AUTOSAR XML (schema 4-2-1)
package /RootP_ASWC_M412
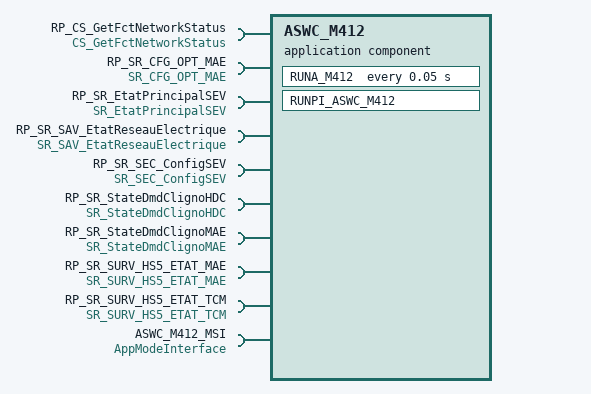
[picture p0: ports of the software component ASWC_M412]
  application sw component type ASWC_M412
    provide/require port PRP_SR_ManTurnIDReq: nonqueued-receiver-com-spec{data-element=ManTurnIDReq, enable-update=0, handle-data-status=1, handle-never-received=0, init-value=CONST_t_IndicatorDirection_0:0}, provided-required-interface=SR_ManTurnIDReq
    10 x require port:
      RP_CS_GetFctNetworkStatus: required-interface=CS_GetFctNetworkStatus
      RP_SR_CFG_OPT_MAE: nonqueued-receiver-com-spec{data-element=CFG_OPT_MAE, enable-update=0, handle-data-status=1, handle-never-received=0, init-value=CONST_tBYTE_0:0}, required-interface=SR_CFG_OPT_MAE
      RP_SR_EtatPrincipalSEV: nonqueued-receiver-com-spec{data-element=EtatPrincipalSEV, enable-update=0, handle-data-status=1, handle-never-received=0, init-value=CONST_EtatPrincipalSEV_t_SEV_SEV_Arret:105}, required-interface=SR_EtatPrincipalSEV
      RP_SR_SAV_EtatReseauElectrique: nonqueued-receiver-com-spec{data-element=SAV_EtatReseauElectrique, enable-update=0, handle-data-status=1, handle-never-received=0, init-value=CONST_t_cGEE_1_0:0}, required-interface=SR_SAV_EtatReseauElectrique
      RP_SR_SEC_ConfigSEV: nonqueued-receiver-com-spec{data-element=SEC_ConfigSEV, enable-update=0, handle-data-status=1, handle-never-received=0, init-value=CONST_t_cCSEV_4:4}, required-interface=SR_SEC_ConfigSEV
      RP_SR_StateDmdClignoHDC: nonqueued-receiver-com-spec{data-element=StateDmdClignoHDC, enable-update=0, handle-data-status=1, handle-never-received=0, init-value=CONST_StateDmdClignoHDC_t_IndicatorDirection_cNoID:0}, required-interface=SR_StateDmdClignoHDC
      RP_SR_StateDmdClignoMAE: nonqueued-receiver-com-spec{data-element=StateDmdClignoMAE, enable-update=0, handle-data-status=1, handle-never-received=0, init-value=CONST_StateDmdClignoMAE_t_IndicatorDirection_cNoID:0}, required-interface=SR_StateDmdClignoMAE
      RP_SR_SURV_HS5_ETAT_MAE: nonqueued-receiver-com-spec{data-element=deSurvHs5EtatMae, alive-timeout=600, enable-update=0, handle-data-status=1, handle-never-received=0, init-value=CONST_tLOG_0:0}, required-interface=SR_SURV_HS5_ETAT_MAE
      RP_SR_SURV_HS5_ETAT_TCM: nonqueued-receiver-com-spec{data-element=deSurvHs5EtatTcm, alive-timeout=300, enable-update=0, handle-data-status=1, handle-never-received=0, init-value=CONST_tLOG_0:0}, required-interface=SR_SURV_HS5_ETAT_TCM
      ASWC_M412_MSI: required-interface=AppModeInterface
    behavior IB_ASWC_M412: data-type-mapping=ApplicationModeMapping, handle-termination-and-restart=NO-SUPPORT
      timing event RUNA_M412_Cyclic: start-on-event=RUNA_M412, period=0.05
        disabled-mode:
          ASWC_M412_MSI.AppMode.APP_WAKEUP
          ASWC_M412_MSI.AppMode.APP_OFF
          ASWC_M412_MSI.AppMode.APP_SYNC_INIT
          ASWC_M412_MSI.AppMode.APP_CONFIG
      swc mode switch event RUNPI_ASWC_M412_ENTRY: start-on-event=RUNPI_ASWC_M412, activation=ON-ENTRY, mode=ASWC_M412_MSI.AppMode.APP_WAKEUP
      runnable RUNA_M412
        data-read-access:
          9 x access:
            dra_RP_SR_EtatPrincipalSEV_EtatPrincipalSEV: accessed-variable=RP_SR_EtatPrincipalSEV.EtatPrincipalSEV
            dra_RP_SR_SAV_EtatReseauElectrique_SAV_EtatReseauElectrique: accessed-variable=RP_SR_SAV_EtatReseauElectrique.SAV_EtatReseauElectrique
            dra_RP_SR_SEC_ConfigSEV_SEC_ConfigSEV: accessed-variable=RP_SR_SEC_ConfigSEV.SEC_ConfigSEV
            dra_RP_SR_StateDmdClignoHDC_StateDmdClignoHDC: accessed-variable=RP_SR_StateDmdClignoHDC.StateDmdClignoHDC
            dra_RP_SR_StateDmdClignoMAE_StateDmdClignoMAE: accessed-variable=RP_SR_StateDmdClignoMAE.StateDmdClignoMAE
            dra_RP_SR_SURV_HS5_ETAT_MAE_deSurvHs5EtatMae: accessed-variable=RP_SR_SURV_HS5_ETAT_MAE.deSurvHs5EtatMae
            dra_RP_SR_SURV_HS5_ETAT_TCM_deSurvHs5EtatTcm: accessed-variable=RP_SR_SURV_HS5_ETAT_TCM.deSurvHs5EtatTcm
            dra_RP_SR_CFG_OPT_MAE_CFG_OPT_MAE: accessed-variable=RP_SR_CFG_OPT_MAE.CFG_OPT_MAE
            dra_PRP_SR_ManTurnIDReq_ManTurnIDReq: accessed-variable=PRP_SR_ManTurnIDReq.ManTurnIDReq
        data-write-access:
          access dwa_PRP_SR_ManTurnIDReq_ManTurnIDReq: accessed-variable=PRP_SR_ManTurnIDReq.ManTurnIDReq
        sync call sscp_RUNA_M412_CS_GetFctNetworkStatus_Get: operation=RP_CS_GetFctNetworkStatus.Get, timeout=0
      runnable RUNPI_ASWC_M412
package /RootP_Implementatation
  swc implementation Implementatation_ASWC_M412: programming-language=C, sw-version=1.0.0, vendor-id=1, behavior=IB_ASWC_M412
    code-descriptors:
      code SRC: artifact-descriptors=autosar-engineering-object={short-label=EngObject, category=SWSRC}
    resource consumption Resources
